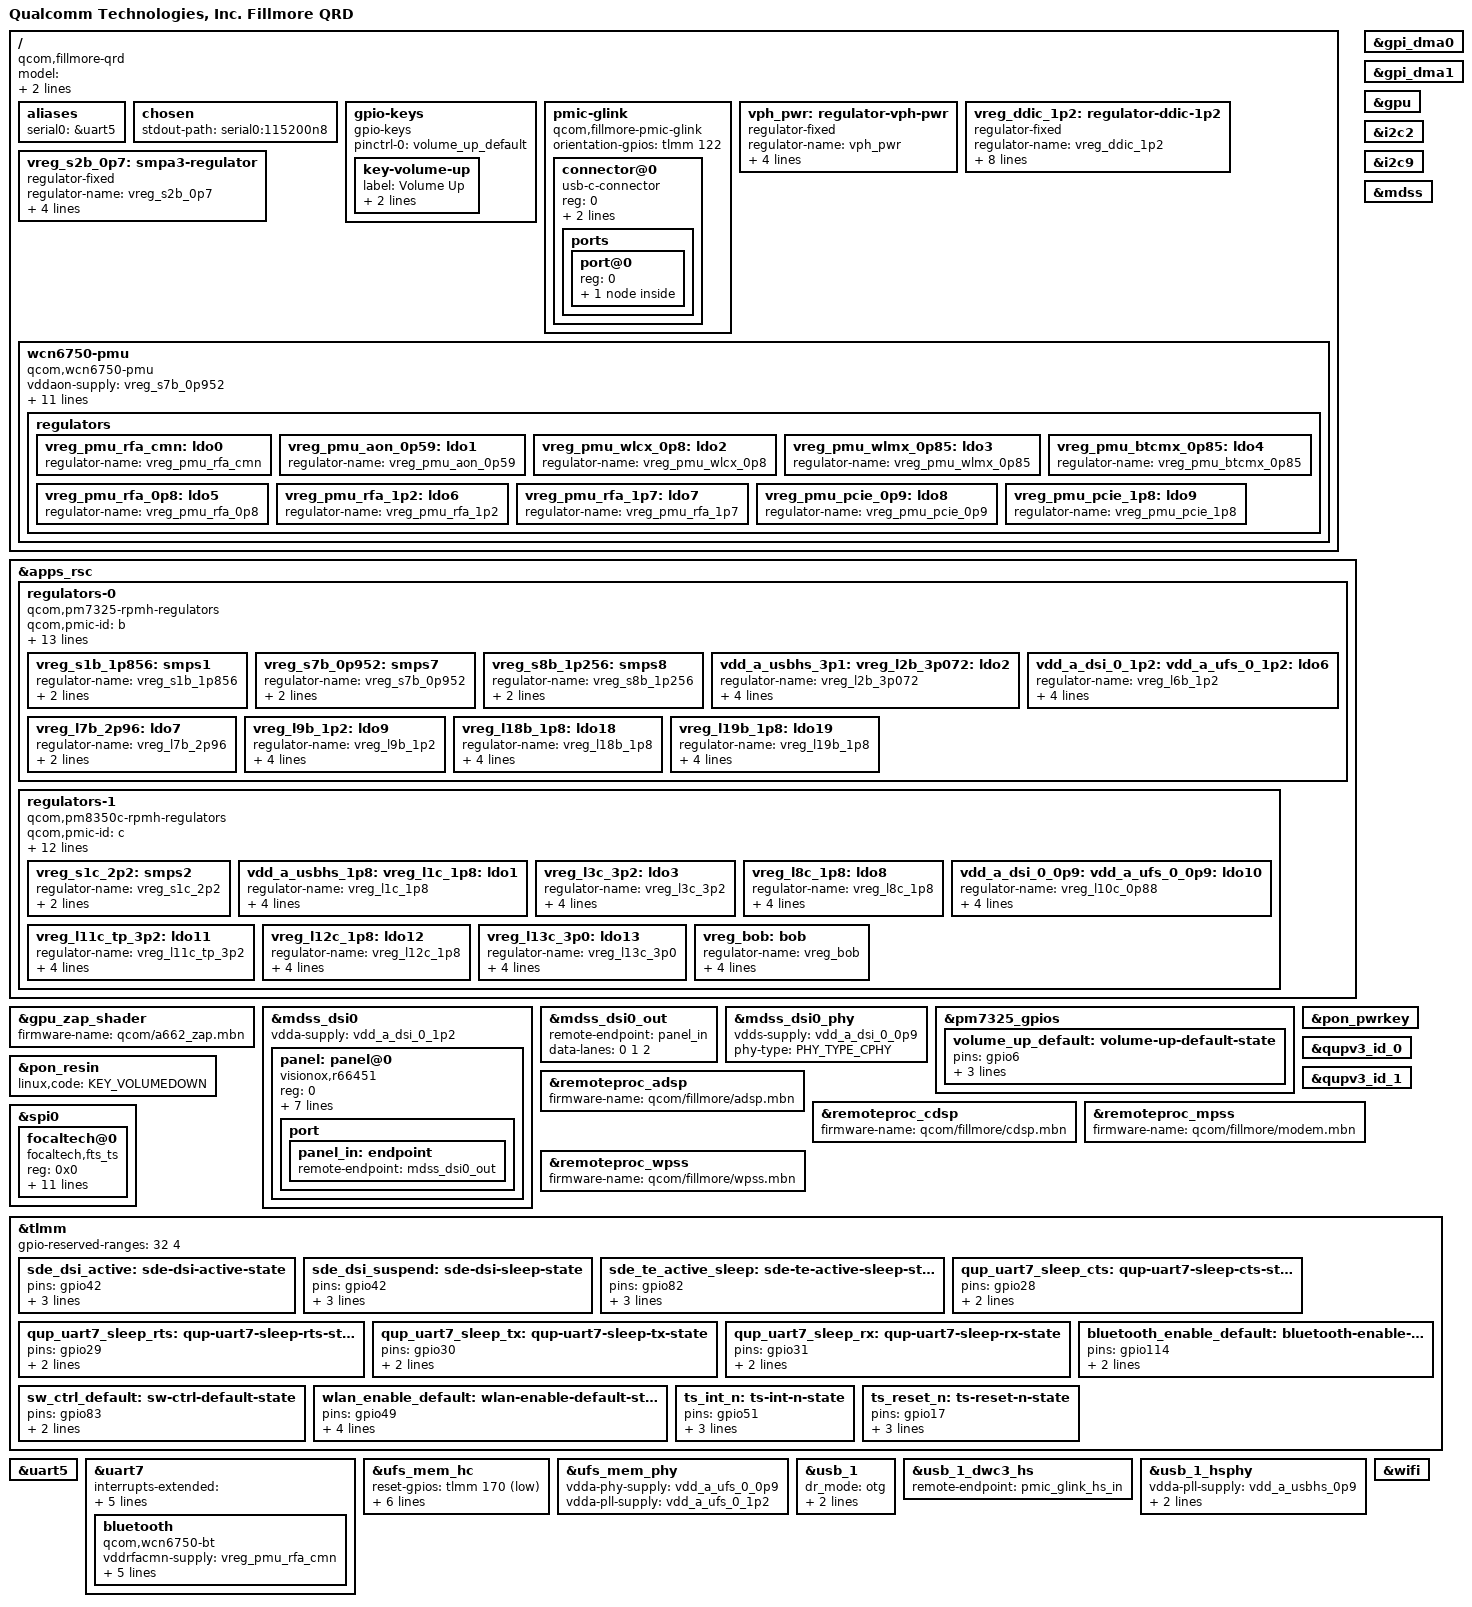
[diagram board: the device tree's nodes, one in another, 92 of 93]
// SPDX-License-Identifier: GPL-2.0-only
/*
 * Copyright (c) 2025, Aelin Reidel <aelin@mainlining.org>
 */

/dts-v1/;

#include <dt-bindings/phy/phy.h>
#include <dt-bindings/pinctrl/qcom,pmic-gpio.h>
#include <dt-bindings/regulator/qcom,rpmh-regulator.h>
#include "fillmore.dtsi"
#include "pm7325.dtsi"
#include "pm8350c.dtsi"
#include "pmk8350.dtsi"

/ {
	model = "Qualcomm Technologies, Inc. Fillmore QRD";
	compatible = "qcom,fillmore-qrd", "qcom,fillmore";
	chassis-type = "handset";

	aliases {
		serial0 = &uart5;
	};

	chosen {
		#address-cells = <2>;
		#size-cells = <2>;
		ranges;

		stdout-path = "serial0:115200n8";

		/*
		framebuffer0: framebuffer@b8000000 {
			compatible = "simple-framebuffer";
			reg = <0x0 0xb8000000 0x0 0x2b00000>;
			width = <1080>;
			height = <2340>;
			stride = <(1080 * 4)>;
			format = "a8r8g8b8";

			clocks = <&gcc GCC_DISP_HF_AXI_CLK>,
				 <&gcc GCC_DISP_SF_AXI_CLK>,
				 <&dispcc DISP_CC_MDSS_MDP_CLK>,
				 <&dispcc DISP_CC_MDSS_BYTE0_CLK>,
				 <&dispcc DISP_CC_MDSS_BYTE0_INTF_CLK>,
				 <&dispcc DISP_CC_MDSS_PCLK0_CLK>,
				 <&dispcc DISP_CC_MDSS_VSYNC_CLK>;
			power-domains = <&dispcc DISP_CC_MDSS_CORE_GDSC>;
		};
		*/
	};

	gpio-keys {
		compatible = "gpio-keys";

		pinctrl-0 = <&volume_up_default>;
		pinctrl-names = "default";

		key-volume-up {
			label = "Volume Up";
			gpios = <&pm7325_gpios 6 GPIO_ACTIVE_LOW>;
			linux,code = <KEY_VOLUMEUP>;
		};
	};

	pmic-glink {
		compatible = "qcom,fillmore-pmic-glink",
			     "qcom,sm8450-pmic-glink",
			     "qcom,pmic-glink";
		#address-cells = <1>;
		#size-cells = <0>;
		orientation-gpios = <&tlmm 122 GPIO_ACTIVE_HIGH>;

		connector@0 {
			compatible = "usb-c-connector";
			reg = <0>;

			power-role = "dual";
			data-role = "dual";

			ports {
				#address-cells = <1>;
				#size-cells = <0>;

				port@0 {
					reg = <0>;

					pmic_glink_hs_in: endpoint {
						remote-endpoint = <&usb_1_dwc3_hs>;
					};
				};
			};
		};
	};

	/*
	reserved-memory {
		splash_region@b8000000 {
			reg = <0x0 0xb8000000 0x0 0x2b00000>;
			no-map;
		};
	};
	*/

	vph_pwr: regulator-vph-pwr {
		compatible = "regulator-fixed";

		regulator-name = "vph_pwr";
		regulator-min-microvolt = <3700000>;
		regulator-max-microvolt = <3700000>;

		regulator-always-on;
		regulator-boot-on;
	};

	vreg_ddic_1p2: regulator-ddic-1p2 {
		compatible = "regulator-fixed";
		regulator-name = "vreg_ddic_1p2";

		regulator-min-microvolt = <1200000>;
		regulator-max-microvolt = <1200000>;
		regulator-enable-ramp-delay = <233>;

		gpio = <&tlmm 148 GPIO_ACTIVE_HIGH>;
		enable-active-high;

		vin-supply = <&vreg_s8b_1p256>;

		regulator-always-on;
		regulator-boot-on;
	};

	/* S2B is really ebi.lvl but it's there for supply map completeness sake */
	vreg_s2b_0p7: smpa3-regulator {
		compatible = "regulator-fixed";
		regulator-name = "vreg_s2b_0p7";

		regulator-min-microvolt = <65535>;
		regulator-max-microvolt = <65535>;
		regulator-always-on;
		vin-supply = <&vph_pwr>;
	};

	wcn6750-pmu {
		compatible = "qcom,wcn6750-pmu";

		vddaon-supply = <&vreg_s7b_0p952>;
		vddasd-supply = <&vreg_l11c_tp_3p2>;
		vddpmu-supply = <&vreg_s7b_0p952>;
		vddrfa0p8-supply = <&vreg_s7b_0p952>;
		vddrfa1p2-supply = <&vreg_s8b_1p256>;
		vddrfa1p7-supply = <&vreg_s1b_1p856>;
		vddrfa2p2-supply = <&vreg_s1c_2p2>;

		wlan-enable-gpios = <&tlmm 49 GPIO_ACTIVE_HIGH>;
		bt-enable-gpios = <&tlmm 114 GPIO_ACTIVE_HIGH>;
		swctrl-gpios = <&tlmm 83 GPIO_ACTIVE_HIGH>;

		pinctrl-0 = <&bluetooth_enable_default>, <&wlan_enable_default>, <&sw_ctrl_default>;
		pinctrl-names = "default";

		regulators {
			vreg_pmu_rfa_cmn: ldo0 {
				regulator-name = "vreg_pmu_rfa_cmn";
			};

			vreg_pmu_aon_0p59: ldo1 {
				regulator-name = "vreg_pmu_aon_0p59";
			};

			vreg_pmu_wlcx_0p8: ldo2 {
				regulator-name = "vreg_pmu_wlcx_0p8";
			};

			vreg_pmu_wlmx_0p85: ldo3 {
				regulator-name = "vreg_pmu_wlmx_0p85";
			};

			vreg_pmu_btcmx_0p85: ldo4 {
				regulator-name = "vreg_pmu_btcmx_0p85";
			};

			vreg_pmu_rfa_0p8: ldo5 {
				regulator-name = "vreg_pmu_rfa_0p8";
			};

			vreg_pmu_rfa_1p2: ldo6 {
				regulator-name = "vreg_pmu_rfa_1p2";
			};

			vreg_pmu_rfa_1p7: ldo7 {
				regulator-name = "vreg_pmu_rfa_1p7";
			};

			vreg_pmu_pcie_0p9: ldo8 {
				regulator-name = "vreg_pmu_pcie_0p9";
			};

			vreg_pmu_pcie_1p8: ldo9 {
				regulator-name = "vreg_pmu_pcie_1p8";
			};
		};
	};
};

&apps_rsc {
	regulators-0 {
		compatible = "qcom,pm7325-rpmh-regulators";
		qcom,pmic-id = "b";

		vdd-s1-supply = <&vph_pwr>;
		vdd-s2-supply = <&vph_pwr>;
		vdd-s7-supply = <&vph_pwr>;
		vdd-s8-supply = <&vph_pwr>;

		vdd-l1-l4-l12-l15-supply = <&vreg_s7b_0p952>;
		vdd-l2-l7-supply = <&vreg_bob>;
		vdd-l3-supply = <&vreg_s2b_0p7>;
		vdd-l5-supply = <&vreg_s2b_0p7>;
		vdd-l6-l9-l10-supply = <&vreg_s8b_1p256>;
		vdd-l8-supply = <&vreg_s7b_0p952>;
		vdd-l11-l17-l18-l19-supply = <&vreg_s1b_1p856>;
		vdd-l13-supply = <&vreg_s7b_0p952>;
		vdd-l14-l16-supply = <&vreg_s8b_1p256>;

		/*
		 * S2, L4-L5 are ARCs:
		 * S2 - ebi.lvl,
		 * L4 - lmx.lvl,
		 * l5 - lcx.lvl.
		 *
		 * L10 is unused.
		 */

		vreg_s1b_1p856: smps1 {
			regulator-name = "vreg_s1b_1p856";
			regulator-min-microvolt = <1700000>;
			regulator-max-microvolt = <2040000>;
		};

		vreg_s7b_0p952: smps7 {
			regulator-name = "vreg_s7b_0p952";
			regulator-min-microvolt = <598000>;
			regulator-max-microvolt = <1120000>;
		};

		vreg_s8b_1p256: smps8 {
			regulator-name = "vreg_s8b_1p256";
			regulator-min-microvolt = <382000>;
			regulator-max-microvolt = <1510000>;
		};

		vdd_a_usbhs_3p1:
		vreg_l2b_3p072: ldo2 {
			regulator-name = "vreg_l2b_3p072";
			regulator-min-microvolt = <2700000>;
			regulator-max-microvolt = <3544000>;
			regulator-initial-mode = <RPMH_REGULATOR_MODE_HPM>;
		};

		vdd_a_dsi_0_1p2:
		vdd_a_ufs_0_1p2:
		vreg_l6b_1p2: ldo6 {
			regulator-name = "vreg_l6b_1p2";
			regulator-min-microvolt = <1140000>;
			regulator-max-microvolt = <1260000>;
			regulator-initial-mode = <RPMH_REGULATOR_MODE_HPM>;
		};

		vreg_l7b_2p96: ldo7 {
			regulator-name = "vreg_l7b_2p96";
			/*
			 * Remove min/max voltages for this regulator as initial
			 * voltage of L7B is set to be 2.504v/2.952v during PON
			 * depending upon the UFS mode 3.x/2.x. UFS is the only
			 * client on this and this regulator will only be voted
			 * for enabling/disabling conditions.
			 */
			regulator-initial-mode = <RPMH_REGULATOR_MODE_HPM>;
		};

		vreg_l9b_1p2: ldo9 {
			regulator-name = "vreg_l9b_1p2";
			regulator-min-microvolt = <1080000>;
			regulator-max-microvolt = <1304000>;
			regulator-initial-mode = <RPMH_REGULATOR_MODE_HPM>;
		};

		vreg_l18b_1p8: ldo18 {
			regulator-name = "vreg_l18b_1p8";
			regulator-min-microvolt = <1504000>;
			regulator-max-microvolt = <2000000>;
			regulator-initial-mode = <RPMH_REGULATOR_MODE_HPM>;
		};

		vreg_l19b_1p8: ldo19 {
			regulator-name = "vreg_l19b_1p8";
			regulator-min-microvolt = <1700000>;
			regulator-max-microvolt = <1950000>;
			regulator-initial-mode = <RPMH_REGULATOR_MODE_HPM>;
		};
	};

	regulators-1 {
		compatible = "qcom,pm8350c-rpmh-regulators";
		qcom,pmic-id = "c";

		vdd-s1-supply = <&vph_pwr>;
		vdd-s2-supply = <&vph_pwr>;
		vdd-s5-supply = <&vph_pwr>;
		vdd-s7-supply = <&vph_pwr>;
		vdd-s9-supply = <&vph_pwr>;
		vdd-s10-supply = <&vph_pwr>;

		vdd-l1-l12-supply = <&vreg_s1b_1p856>;
		vdd-l2-l8-supply = <&vreg_s1b_1p856>;
		vdd-l3-l4-l5-l7-l13-supply = <&vreg_bob>;
		vdd-l6-l9-l11-supply = <&vreg_bob>;
		vdd-l10-supply = <&vreg_s7b_0p952>;

		vdd-bob-supply = <&vph_pwr>;

		/*
		 * S2, S4, S5, S6, S8, S10 are ARCs:
		 * S2  - gfx.lvl,
		 * S4  - mxc.lvl,
		 * S5  - mmcx.lvl,
		 * S6  - mms.lvl,
		 * S8  - cx.lvl,
		 * S10 - mx.lvl.
		 */

		vreg_s1c_2p2: smps2 {
			regulator-name = "vreg_s1c_2p2";
			regulator-min-microvolt = <850000>;
			regulator-max-microvolt = <2200000>;
		};

		vdd_a_usbhs_1p8:
		vreg_l1c_1p8: ldo1 {
			regulator-name = "vreg_l1c_1p8";
			regulator-min-microvolt = <1620000>;
			regulator-max-microvolt = <1980000>;
			regulator-initial-mode = <RPMH_REGULATOR_MODE_HPM>;
		};

		vreg_l3c_3p2: ldo3 {
			regulator-name = "vreg_l3c_3p2";
			regulator-min-microvolt = <2700000>;
			regulator-max-microvolt = <3544000>;
			regulator-initial-mode = <RPMH_REGULATOR_MODE_HPM>;
		};

		vreg_l8c_1p8: ldo8 {
			regulator-name = "vreg_l8c_1p8";
			regulator-min-microvolt = <1620000>;
			regulator-max-microvolt = <2000000>;
			regulator-initial-mode = <RPMH_REGULATOR_MODE_HPM>;
		};

		vdd_a_dsi_0_0p9:
		vdd_a_ufs_0_0p9:
		vdd_a_usbhs_0p9:
		vreg_l10c_0p88: ldo10 {
			regulator-name = "vreg_l10c_0p88";
			regulator-min-microvolt = <720000>;
			regulator-max-microvolt = <1050000>;
			regulator-initial-mode = <RPMH_REGULATOR_MODE_HPM>;
		};

		vreg_l11c_tp_3p2: ldo11 {
			regulator-name = "vreg_l11c_tp_3p2";
			regulator-min-microvolt = <1650000>;
			regulator-max-microvolt = <3544000>;
			regulator-initial-mode = <RPMH_REGULATOR_MODE_HPM>;
		};

		vreg_l12c_1p8: ldo12 {
			regulator-name = "vreg_l12c_1p8";
			regulator-min-microvolt = <1650000>;
			regulator-max-microvolt = <2000000>;
			regulator-initial-mode = <RPMH_REGULATOR_MODE_HPM>;
		};

		vreg_l13c_3p0: ldo13 {
			regulator-name = "vreg_l13c_3p0";
			regulator-min-microvolt = <2700000>;
			regulator-max-microvolt = <3300000>;
			regulator-initial-mode = <RPMH_REGULATOR_MODE_HPM>;
		};

		vreg_bob: bob {
			regulator-name = "vreg_bob";
			regulator-min-microvolt = <3008000>;
			regulator-max-microvolt = <3960000>;
			regulator-initial-mode = <RPMH_REGULATOR_MODE_AUTO>;
		};
	};
};

&gpi_dma0 {
	status = "okay";
};

&gpi_dma1 {
	status = "okay";
};

&gpu {
	status = "okay";
};

&gpu_zap_shader {
	firmware-name = "qcom/a662_zap.mbn";
};

&i2c2 {
	/* pm8010i @ 8 */
	/* pm8010i @ 9 */
	/* pm8010j @ c */
	/* pm8010j @ d */
	/* onnn,redriver @ 1c */
	/* fsa4480 @ 42 */
	/* rtc6226 @ 64 */

	status = "okay";
};

&i2c9 {
	/* qcom,sn-nci @ 28 */

	status = "okay";
};

&mdss {
	status = "okay";
};

&mdss_dsi0 {
	vdda-supply = <&vdd_a_dsi_0_1p2>;

	status = "okay";

	panel: panel@0 {
		compatible = "visionox,r66451";
		reg = <0>;

		reset-gpios = <&tlmm 42 GPIO_ACTIVE_LOW>;
		te-gpios = <&tlmm 82 GPIO_ACTIVE_HIGH>;

		vddio-supply = <&vreg_l12c_1p8>;
		vdd-supply = <&vreg_l13c_3p0>;

		pinctrl-0 = <&sde_dsi_active>, <&sde_te_active_sleep>;
		pinctrl-1 = <&sde_dsi_suspend>, <&sde_te_active_sleep>;
		pinctrl-names = "default", "sleep";

		port {
			panel_in: endpoint {
				remote-endpoint = <&mdss_dsi0_out>;
			};
		};
	};
};

&mdss_dsi0_out {
	remote-endpoint = <&panel_in>;
	data-lanes = <0 1 2>;
};

&mdss_dsi0_phy {
	vdds-supply = <&vdd_a_dsi_0_0p9>;

	phy-type = <PHY_TYPE_CPHY>;

	status = "okay";
};

&pm7325_gpios {
	volume_up_default: volume-up-default-state {
		pins = "gpio6";
		function = PMIC_GPIO_FUNC_NORMAL;
		power-source = <1>;
		bias-pull-up;
	};
};

&pon_pwrkey {
	status = "okay";
};

&pon_resin {
	linux,code = <KEY_VOLUMEDOWN>;

	status = "okay";
};

&qupv3_id_0 {
	status = "okay";
};

&qupv3_id_1 {
	status = "okay";
};

&remoteproc_adsp {
	firmware-name = "qcom/fillmore/adsp.mbn";

	status = "okay";
};

&remoteproc_cdsp {
	firmware-name = "qcom/fillmore/cdsp.mbn";

	status = "okay";
};

&remoteproc_mpss {
	firmware-name = "qcom/fillmore/modem.mbn";

	status = "okay";
};

&remoteproc_wpss {
	firmware-name = "qcom/fillmore/wpss.mbn";

	status = "okay";
};

&spi0 {
	status = "okay";

	focaltech@0 {
		compatible = "focaltech,fts_ts";
		reg = <0x0>;

		spi-max-frequency = <6000000>;

		interrupts-extended = <&tlmm 51 IRQ_TYPE_LEVEL_LOW>;
		/* Actually active low */
		reset-gpios = <&tlmm 17 GPIO_ACTIVE_HIGH>;
		irq-gpio = <&tlmm 51 IRQ_TYPE_LEVEL_LOW>;
		focaltech,display-coords = <0 0 1080 2340>;
		focaltech,max-touch-number = <5>;
		focaltech,ic-type = <0x3658d488>;

		vdd-supply = <&vreg_l3c_3p2>;
		/* Guesswork */
		iovdd-supply = <&vreg_l8c_1p8>;

		pinctrl-names = "default";
		pinctrl-0 = <&ts_int_n>,
			    <&ts_reset_n>;
	};
};

&tlmm {
	gpio-reserved-ranges = <32 4>; /* NFC secure element */

	sde_dsi_active: sde-dsi-active-state {
		pins = "gpio42";
		function = "gpio";
		drive-strength = <8>;
		bias-disable;
	};

	sde_dsi_suspend: sde-dsi-sleep-state {
		pins = "gpio42";
		function = "gpio";
		drive-strength = <2>;
		bias-pull-down;
	};

	sde_te_active_sleep: sde-te-active-sleep-state {
		pins = "gpio82";
		function = "mdp_vsync";
		drive-strength = <2>;
		bias-pull-down;
	};

	qup_uart7_sleep_cts: qup-uart7-sleep-cts-state {
		pins = "gpio28";
		function = "gpio";
		/*
		 * Configure a bias-bus-hold on CTS to lower power
		 * usage when Bluetooth is turned off. Bus hold will
		 * maintain a low power state regardless of whether
		 * the Bluetooth module drives the pin in either
		 * direction or leaves the pin fully unpowered.
		 */
		bias-bus-hold;
	};

	qup_uart7_sleep_rts: qup-uart7-sleep-rts-state {
		pins = "gpio29";
		function = "gpio";
		/*
		 * Configure pull-down on RTS. As RTS is active low
		 * signal, pull it low to indicate the BT SoC that it
		 * can wakeup the system anytime from suspend state by
		 * pulling RX low (by sending wakeup bytes).
		 */
		bias-pull-down;
	};

	qup_uart7_sleep_tx: qup-uart7-sleep-tx-state {
		pins = "gpio30";
		function = "gpio";
		/*
		 * Configure pull-up on TX when it isn't actively driven
		 * to prevent BT SoC from receiving garbage during sleep.
		 */
		bias-pull-up;
	};

	qup_uart7_sleep_rx: qup-uart7-sleep-rx-state {
		pins = "gpio31";
		function = "gpio";
		/*
		 * Configure a pull-up on RX. This is needed to avoid
		 * garbage data when the TX pin of the Bluetooth module
		 * is floating which may cause spurious wakeups.
		 */
		bias-pull-up;
	};

	bluetooth_enable_default: bluetooth-enable-default-state {
		pins = "gpio114";
		function = "gpio";
		bias-pull-down;
	};

	sw_ctrl_default: sw-ctrl-default-state {
		pins = "gpio83";
		function = "gpio";
		bias-pull-down;
	};

	wlan_enable_default: wlan-enable-default-state {
		pins = "gpio49";
		function = "gpio";
		drive-strength = <16>;
		output-high;
		bias-pull-up;
	};

	ts_int_n: ts-int-n-state {
		pins = "gpio51";
		function = "gpio";
		drive-strength = <8>;
		bias-pull-up;
	};

	ts_reset_n: ts-reset-n-state {
		pins = "gpio17";
		function = "gpio";
		drive-strength = <8>;
		bias-pull-up;
	};
};

&uart5 {
	status = "okay";
};

&uart7 {
	/delete-property/ interrupts;
	interrupts-extended = <&intc GIC_SPI 608 IRQ_TYPE_LEVEL_HIGH>,
			      <&tlmm 31 IRQ_TYPE_EDGE_FALLING>;

	pinctrl-1 =  <&qup_uart7_sleep_cts>,
		     <&qup_uart7_sleep_rts>,
		     <&qup_uart7_sleep_tx>,
		     <&qup_uart7_sleep_rx>;
	pinctrl-names = "default",
			"sleep";

	status = "okay";

	bluetooth {
		compatible = "qcom,wcn6750-bt";

		vddrfacmn-supply = <&vreg_pmu_rfa_cmn>;
		vddaon-supply = <&vreg_pmu_aon_0p59>;
		vddbtcmx-supply = <&vreg_pmu_btcmx_0p85>;
		vddrfa0p8-supply = <&vreg_pmu_rfa_0p8>;
		vddrfa1p7-supply = <&vreg_pmu_rfa_1p7>;
		vddrfa1p2-supply = <&vreg_pmu_rfa_1p2>;
	};
};

&ufs_mem_hc {
	reset-gpios = <&tlmm 170 GPIO_ACTIVE_LOW>;

	vcc-supply = <&vreg_l7b_2p96>;
	vcc-max-microamp = <1100000>;

	vccq-supply = <&vreg_l9b_1p2>;
	vccq-max-microamp = <1200000>;

	vccq2-supply = <&vreg_l19b_1p8>;
	vccq2-max-microamp = <800000>;

	status = "okay";
};

&ufs_mem_phy {
	vdda-phy-supply = <&vdd_a_ufs_0_0p9>;
	vdda-pll-supply = <&vdd_a_ufs_0_1p2>;

	status = "okay";
};

&usb_1 {
	dr_mode = "otg";

	maximum-speed = "high-speed";

	/* Limit to USB 2.0 only for now */
	qcom,select-utmi-as-pipe-clk;

	status = "okay";
};

&usb_1_dwc3_hs {
	remote-endpoint = <&pmic_glink_hs_in>;
};

&usb_1_hsphy {
	vdda-pll-supply = <&vdd_a_usbhs_0p9>;
	vdda18-supply = <&vdd_a_usbhs_1p8>;
	vdda33-supply = <&vdd_a_usbhs_3p1>;

	status = "okay";
};

&wifi {
	status = "okay";
};
